# BS2X register map
File version: 0.1
CPU: other r0p0, little endian, MPU, FPU, 3 interrupt priority bits
Registers are 32-bit, read-write, reset 0x0 unless marked. A register's access mark holds for its fields unless they carry their own. Offsets are from the block's base; [hi:lo] are bit positions.

## SPI0 — SPI0 master/slave controller (SSI v151)
Base 0x52087000
Same registers: SPI1 0x52088000, SPI2 0x52089000
0x00 SPI_ER — SPI enable register
  [0] spi_en — SPI enable: 0=disabled; 1=enabled
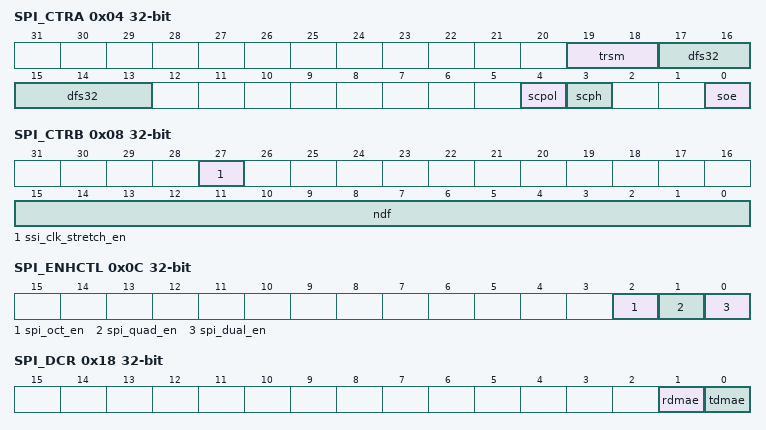
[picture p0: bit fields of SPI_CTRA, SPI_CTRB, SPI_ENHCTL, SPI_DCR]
0x04 SPI_CTRA — SPI control register 0
  [19:18] trsm — Transfer mode: 00=TX/RX; 01=TX only; 10=RX only
    0=TxRx (Transmit and Receive); 1=TxOnly (Transmit Only); 2=RxOnly (Receive Only)
  [17:13] dfs32 — Data frame size in 32-bit mode (0=4bit; up to 31=35bit)
  [4] scpol — Clock polarity: 0=low idle; 1=high idle
    0=LowIdle (SCK idle low); 1=HighIdle (SCK idle high)
  [3] scph — Clock phase: 0=first edge sample; 1=second edge sample
    0=FirstEdge (Sample on first clock edge); 1=SecondEdge (Sample on second clock edge)
  [0] soe — Shift register loop test: 0=normal; 1=loopback
0x08 SPI_CTRB — SPI control register 1 (master only)
  [27] ssi_clk_stretch_en — Clock stretch enable
  [15:0] ndf — Number of data frames (master TX only mode)
0x0C SPI_ENHCTL — Enhanced control register (Dual/Quad/Octal)
  [2] spi_oct_en — Octal SPI mode enable
  [1] spi_quad_en — Quad SPI mode enable
  [0] spi_dual_en — Dual SPI mode enable
0x14 SPI_BRS — Baud rate select register
  [15:0] clk_div — Clock divider (master): SCK = SSI_CLK / (2 * (1 + CLK_DIV))
0x18 SPI_DCR — DMA control register
  [1] rdmae — RX DMA enable
  [0] tdmae — TX DMA enable
0x1C SPI_DRDL — DMA RX data level
  [7:0] dma_rx_data_level — DMA RX FIFO threshold
0x20 SPI_DTDL — DMA TX data level
  [7:0] dma_tx_data_level — DMA TX FIFO threshold
0x60 SPI_DR — Data register (FIFO read/write)
  [31:0] dr — Write: push to TX FIFO; Read: pop from RX FIFO
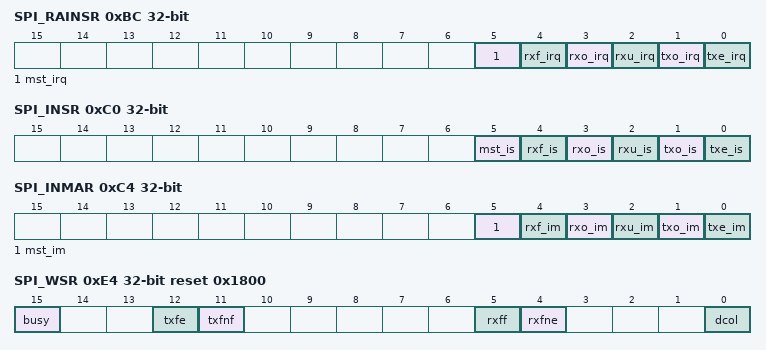
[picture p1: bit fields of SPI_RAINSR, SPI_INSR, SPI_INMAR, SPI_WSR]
0xBC SPI_RAINSR — Raw interrupt status register
  [5] mst_irq ro — Multi-master contention raw status
  [4] rxf_irq ro — RX FIFO full raw status
  [3] rxo_irq ro — RX FIFO overflow raw status
  [2] rxu_irq ro — RX FIFO underflow raw status
  [1] txo_irq ro — TX FIFO overflow raw status
  [0] txe_irq ro — TX FIFO empty raw status
0xC0 SPI_INSR — Interrupt status register (masked)
  [5] mst_is ro — Multi-master interrupt status
  [4] rxf_is ro — RX full interrupt status
  [3] rxo_is ro — RX overflow interrupt status
  [2] rxu_is ro — RX underflow interrupt status
  [1] txo_is ro — TX overflow interrupt status
  [0] txe_is ro — TX empty interrupt status
0xC4 SPI_INMAR — Interrupt mask register
  [5] mst_im — Multi-master interrupt mask
  [4] rxf_im — RX full interrupt mask
  [3] rxo_im — RX overflow interrupt mask
  [2] rxu_im — RX underflow interrupt mask
  [1] txo_im — TX overflow interrupt mask
  [0] txe_im — TX empty interrupt mask
0xC8 SPI_SLENR — Slave enable register (master only)
  [0] slave_enable — Slave select enable
0xCC SPI_TWLR — TX FIFO threshold level
  [7:0] tx_fifo_threshold
0xD0 SPI_TLR — TX FIFO level register
  [7:0] tx_fifo_level ro — TX FIFO data level
0xD8 SPI_RWLR — RX FIFO threshold level
  [7:0] rx_fifo_threshold
0xDC SPI_RLR — RX FIFO level register
  [7:0] rx_fifo_level ro — RX FIFO data level
0xE4 SPI_WSR reset 0x1800 — Status register. Bit layout matches the HiSilicon SSI v151 silicon (vendor hal_spi_v151_regs_def.h spi_wsr_data), NOT the textbook DesignWare SR: the FIFO/busy flags are spread out, not packed in bits 0..6. Verified on WS63 silicon 2026-06-14 (idle reads 0x1800 = TXFNF | TXFE).
  [15] busy ro — SPI busy flag (serial transfer in progress)
  [12] txfe ro — TX FIFO empty
  [11] txfnf ro — TX FIFO not full
  [5] rxff ro — RX FIFO full
  [4] rxfne ro — RX FIFO not empty
  [0] dcol ro — Data collision error (master): the last transfer was halted because another master asserted ss_in_n. Cleared on read.
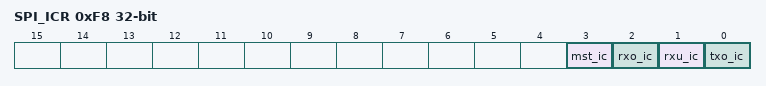
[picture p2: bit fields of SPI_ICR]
0xF8 SPI_ICR — Interrupt clear register
  [3] mst_ic wo — Multi-master interrupt clear
  [2] rxo_ic wo — RX overflow interrupt clear
  [1] rxu_ic wo — RX underflow interrupt clear
  [0] txo_ic wo — TX overflow interrupt clear
